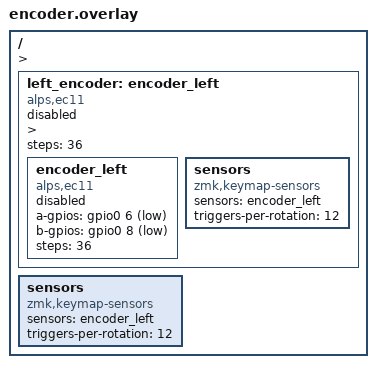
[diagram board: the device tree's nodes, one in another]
#include <dt-bindings/zmk/matrix_transform.h>

/ {
 
        left_encoder: encoder_left {
        compatible = "alps,ec11";
        a-gpios = <&gpio0 6 encoder_left: encoder_left {
        compatible = "alps,ec11";
              a-gpios = <&gpio0 6 (GPIO_ACTIVE_LOW | GPIO_PULL_UP)>;
               b-gpios = <&gpio0 8 (GPIO_ACTIVE_LOW | GPIO_PULL_UP)>;
        steps = <36>;
              status = "disabled";
    };

        sensors: sensors {
            compatible = "zmk,keymap-sensors";
            sensors = <&encoder_left >;
            triggers-per-rotation = <12>;
    };>;
        steps = <36>;
               status = "disabled";
    };

        sensors: sensors {
            compatible = "zmk,keymap-sensors";
            sensors = <&encoder_left >;
            triggers-per-rotation = <12>;
    };
    >;


};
